VERSION "f32"

NS_ :

BS_:

BU_: C70 VC MCU BMS CHG DASH PBX

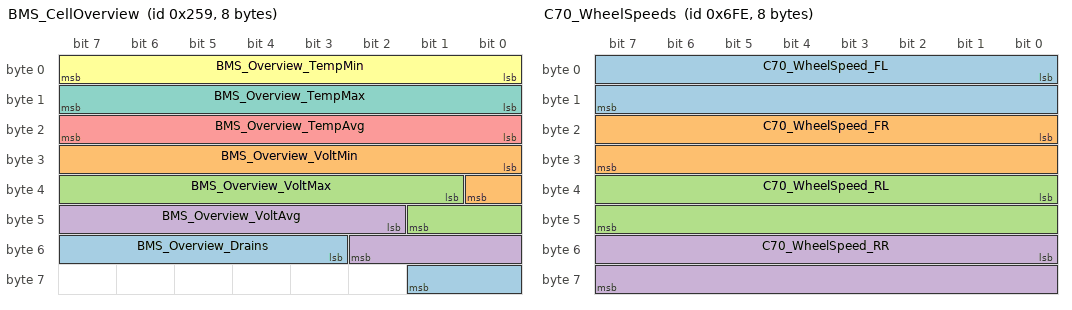
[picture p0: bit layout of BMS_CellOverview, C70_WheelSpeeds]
BO_ 601 BMS_CellOverview: 8 BMS
 SG_ BMS_Overview_Drains : 51|7@1+ (1,0) [0|76] "" Vector__XXX
 SG_ BMS_Overview_VoltMin : 24|9@1+ (0.01,0) [0|5.12] "V"  DASH
 SG_ BMS_Overview_VoltMax : 33|9@1+ (0.01,0) [0|5.12] "V"  DASH
 SG_ BMS_Overview_VoltAvg : 42|9@1+ (0.01,0) [0|5.12] "V" Vector__XXX
 SG_ BMS_Overview_TempAvg : 16|8@1- (1,0) [-128|127] "C" Vector__XXX
 SG_ BMS_Overview_TempMin : 0|8@1- (1,0) [-128|127] "C" Vector__XXX
 SG_ BMS_Overview_TempMax : 8|8@1- (1,0) [-128|127] "C" Vector__XXX

BO_ 1790 C70_WheelSpeeds: 8 C70
 SG_ C70_WheelSpeed_FL : 0|16@1- (1,0) [0|65536] ""  C70
 SG_ C70_WheelSpeed_FR : 16|16@1- (1,0) [0|65536] ""  C70
 SG_ C70_WheelSpeed_RL : 32|16@1- (1,0) [0|65536] ""  C70
 SG_ C70_WheelSpeed_RR : 48|16@1- (1,0) [0|65536] ""  C70

BO_ 1791 C70_BrakePressures: 8 C70
 SG_ C70_BrakePressureFront : 0|16@1+ (1,0) [0|5000] "psi" Vector__XXX
 SG_ C70_BrakePressureRear : 16|16@1- (0.2,1250) [0|2500] "psi" Vector__XXX

BO_ 301 VC_Status: 8 VC
 SG_ VC_Status_VehicleState : 0|4@1+ (1,0) [0|15] ""  DASH
 SG_ VC_Status_MC_State : 4|4@1+ (1,0) [0|15] ""  DASH

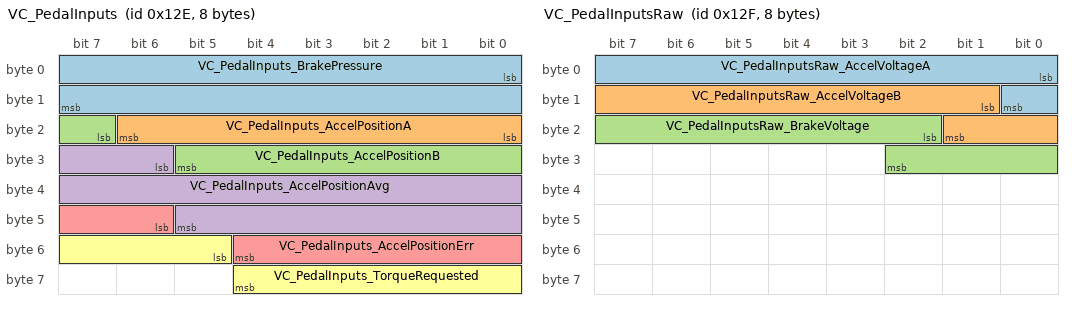
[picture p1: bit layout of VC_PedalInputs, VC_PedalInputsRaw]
BO_ 302 VC_PedalInputs: 8 VC
 SG_ VC_PedalInputs_BrakePressure : 0|16@1+ (0.1,0) [0|3000] "psi" Vector__XXX
 SG_ VC_PedalInputs_AccelPositionA : 16|7@1+ (1,0) [0|100] "%" Vector__XXX
 SG_ VC_PedalInputs_AccelPositionB : 23|7@1+ (1,0) [0|100] "%" Vector__XXX
 SG_ VC_PedalInputs_AccelPositionAvg : 30|16@1+ (0.1,0) [0|100] "%" Vector__XXX
 SG_ VC_PedalInputs_AccelPositionErr : 46|7@1+ (1,0) [0|100] "%" Vector__XXX
 SG_ VC_PedalInputs_TorqueRequested : 53|8@1+ (1,0) [0|254] "Nm" Vector__XXX

BO_ 303 VC_PedalInputsRaw: 8 VC
 SG_ VC_PedalInputsRaw_AccelVoltageA : 0|9@1+ (0.01,0) [0|5] "V" Vector__XXX
 SG_ VC_PedalInputsRaw_AccelVoltageB : 9|9@1+ (0.01,0) [0|5] "V" Vector__XXX
 SG_ VC_PedalInputsRaw_BrakeVoltage : 18|9@1+ (0.01,0) [0|5] "V" Vector__XXX

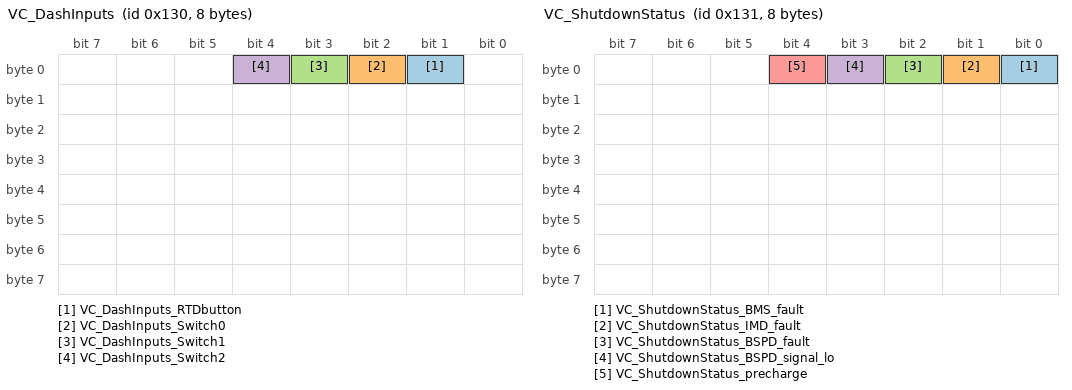
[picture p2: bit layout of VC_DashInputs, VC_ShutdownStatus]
BO_ 304 VC_DashInputs: 8 VC
 SG_ VC_DashInputs_RTDbutton : 1|1@1+ (1,0) [0|1] "" Vector__XXX
 SG_ VC_DashInputs_Switch0 : 2|1@1+ (1,0) [0|1] "" Vector__XXX
 SG_ VC_DashInputs_Switch1 : 3|1@1+ (1,0) [0|1] "" Vector__XXX
 SG_ VC_DashInputs_Switch2 : 4|1@1+ (1,0) [0|1] "" Vector__XXX

BO_ 305 VC_ShutdownStatus: 8 VC
 SG_ VC_ShutdownStatus_BMS_fault : 0|1@1+ (1,0) [0|1] "" Vector__XXX
 SG_ VC_ShutdownStatus_IMD_fault : 1|1@1+ (1,0) [0|1] "" Vector__XXX
 SG_ VC_ShutdownStatus_BSPD_fault : 2|1@1+ (1,0) [0|1] "" Vector__XXX
 SG_ VC_ShutdownStatus_BSPD_signal_lo : 3|1@1+ (1,0) [0|1] "" Vector__XXX
 SG_ VC_ShutdownStatus_precharge : 4|1@1+ (1,0) [0|1] "" Vector__XXX

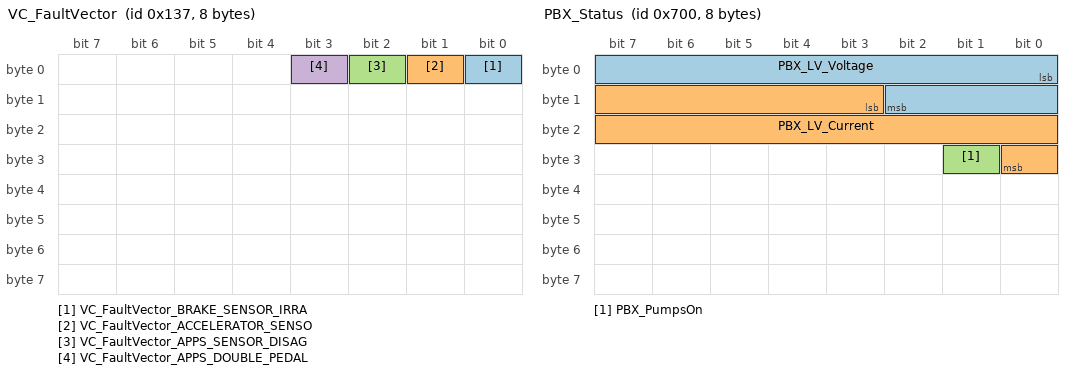
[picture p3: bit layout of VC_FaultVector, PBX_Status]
BO_ 311 VC_FaultVector: 8 VC
 SG_ VC_FaultVector_BRAKE_SENSOR_IRRA : 0|1@1+ (1,0) [0|1] ""  DASH
 SG_ VC_FaultVector_ACCELERATOR_SENSO : 1|1@1+ (1,0) [0|1] ""  DASH
 SG_ VC_FaultVector_APPS_SENSOR_DISAG : 2|1@1+ (1,0) [0|1] ""  DASH
 SG_ VC_FaultVector_APPS_DOUBLE_PEDAL : 3|1@1+ (1,0) [0|1] ""  DASH

BO_ 315 VC_HardFaultIndicator: 8 VC
 SG_ VC_HardFaultIndicator_task : 0|4@1+ (1,0) [0|15] ""  DASH

BO_ 316 VC_RTDSRequest: 8 VC
 SG_ VC_RequestRTDS : 0|1@1+ (1,0) [0|1] "" Vector__XXX

BO_ 1792 PBX_Status: 8 PBX
 SG_ PBX_LV_Voltage : 0|11@1+ (0.01,0) [0|20] "V" Vector__XXX
 SG_ PBX_LV_Current : 11|14@1+ (0.01,0) [0|100] "A" Vector__XXX
 SG_ PBX_PumpsOn : 25|1@1+ (1,0) [0|1] ""  VC

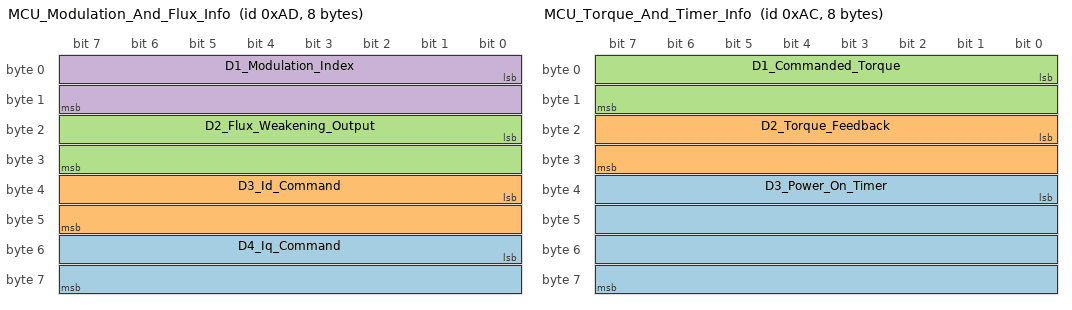
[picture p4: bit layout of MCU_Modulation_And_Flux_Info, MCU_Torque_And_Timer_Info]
BO_ 173 MCU_Modulation_And_Flux_Info: 8 MCU
 SG_ D4_Iq_Command : 48|16@1- (0.1,0) [-3276.8|3276.7] "A" Vector__XXX
 SG_ D3_Id_Command : 32|16@1- (0.1,0) [-3276.8|3276.7] "A" Vector__XXX
 SG_ D2_Flux_Weakening_Output : 16|16@1- (0.1,0) [-3276.8|3276.7] "A" Vector__XXX
 SG_ D1_Modulation_Index : 0|16@1- (0.0001,0) [-3.2768|3.2767] "" Vector__XXX

BO_ 172 MCU_Torque_And_Timer_Info: 8 MCU
 SG_ D3_Power_On_Timer : 32|32@1+ (0.003,0) [0|12884800] "Sec" Vector__XXX
 SG_ D2_Torque_Feedback : 16|16@1- (0.1,0) [-3276.8|3276.7] "Nm" Vector__XXX
 SG_ D1_Commanded_Torque : 0|16@1- (0.1,0) [-3276.8|3276.7] "Nm" Vector__XXX

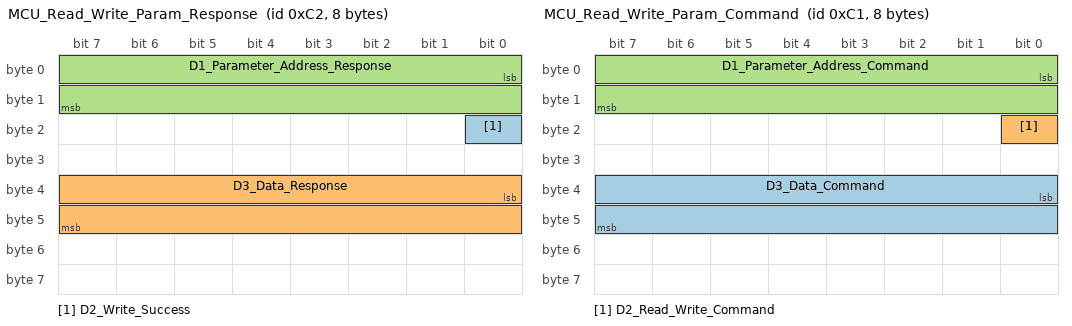
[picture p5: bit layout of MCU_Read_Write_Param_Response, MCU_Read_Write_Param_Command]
BO_ 194 MCU_Read_Write_Param_Response: 8 MCU
 SG_ D2_Write_Success : 16|1@1+ (1,0) [0|1] "" Vector__XXX
 SG_ D3_Data_Response : 32|16@1- (1,0) [-32768|32767] "" Vector__XXX
 SG_ D1_Parameter_Address_Response : 0|16@1+ (1,0) [0|65535] "" Vector__XXX

BO_ 193 MCU_Read_Write_Param_Command: 8 VC
 SG_ D3_Data_Command : 32|16@1- (1,0) [-32768|32767] ""  MCU
 SG_ D2_Read_Write_Command : 16|1@1+ (1,0) [0|1] ""  MCU
 SG_ D1_Parameter_Address_Command : 0|16@1+ (1,0) [0|65535] ""  MCU

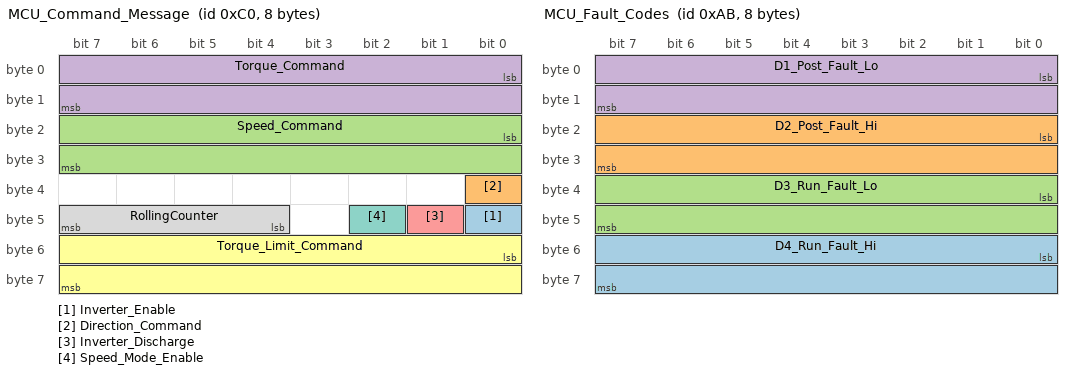
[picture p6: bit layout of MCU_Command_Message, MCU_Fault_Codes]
BO_ 192 MCU_Command_Message: 8 VC
 SG_ Inverter_Enable : 40|1@1+ (1,0) [0|1] "Bit"  MCU
 SG_ Direction_Command : 32|1@1+ (1,0) [0|1] "Bit"  MCU
 SG_ Speed_Command : 16|16@1- (1,0) [-32768|32767] "rpm"  MCU
 SG_ Torque_Command : 0|16@1- (0.1,0) [-3276.8|3276.7] "Nm"  MCU
 SG_ Inverter_Discharge : 41|1@1+ (1,0) [0|1] "Bit"  MCU
 SG_ Torque_Limit_Command : 48|16@1- (0.1,0) [-3276.8|3276.7] "Nm"  MCU
 SG_ Speed_Mode_Enable : 42|1@1+ (1,0) [0|1] "Bit"  MCU
 SG_ RollingCounter : 44|4@1+ (1,0) [0|15] "Bits"  MCU

BO_ 171 MCU_Fault_Codes: 8 MCU
 SG_ D4_Run_Fault_Hi : 48|16@1+ (1,0) [0|65535] "" Vector__XXX
 SG_ D2_Post_Fault_Hi : 16|16@1+ (1,0) [0|65535] "" Vector__XXX
 SG_ D3_Run_Fault_Lo : 32|16@1+ (1,0) [0|65535] "" Vector__XXX
 SG_ D1_Post_Fault_Lo : 0|16@1+ (1,0) [0|65535] "" Vector__XXX

BO_ 170 MCU_Internal_States: 8 MCU
 SG_ D7_Direction_Command : 56|1@1+ (1,0) [0|1] "" Vector__XXX
 SG_ D6_Inverter_Enable_State : 48|1@1+ (1,0) [0|1] "" Vector__XXX
 SG_ D3_Relay_3_Status : 26|1@1+ (1,0) [0|1] "" Vector__XXX
 SG_ D3_Relay_4_Status : 27|1@1+ (1,0) [0|1] "" Vector__XXX
 SG_ D3_Relay_2_Status : 25|1@1+ (1,0) [0|1] "" Vector__XXX
 SG_ D4_Inverter_Run_Mode : 32|1@1+ (1,0) [0|1] "" Vector__XXX
 SG_ D5_Inverter_Command_Mode : 40|1@1+ (1,0) [0|1] "" Vector__XXX
 SG_ D3_Relay_1_Status : 24|1@1+ (1,0) [0|1] "" Vector__XXX
 SG_ D2_Inverter_State : 16|8@1+ (1,0) [0|255] "" Vector__XXX
 SG_ D1_VSM_State : 0|8@1+ (1,0) [0|15] "" Vector__XXX
 SG_ D6_Inverter_Enable_Lockout : 55|1@1+ (1,0) [0|1] "" Vector__XXX
 SG_ D4_Inverter_Discharge_State : 37|3@1+ (1,0) [0|7] "" Vector__XXX
 SG_ D3_Relay_5_Status : 28|1@1+ (1,0) [0|1] "" Vector__XXX
 SG_ D3_Relay_6_Status : 29|1@1+ (1,0) [0|1] "" Vector__XXX
 SG_ D7_BMS_Active : 57|1@1+ (1,0) [0|1] "" Vector__XXX
 SG_ D7_BMS_Torque_Limiting : 58|1@1+ (1,0) [0|1] "" Vector__XXX
 SG_ D7_Max_Speed_Limiting : 59|1@1+ (1,0) [0|1] "" Vector__XXX
 SG_ D7_Low_Speed_Limiting : 61|1@1+ (1,0) [0|1] "" Vector__XXX
 SG_ D5_Rolling_Counter : 44|4@1+ (1,0) [0|15] "" Vector__XXX
 SG_ D1_PWM_Frequency : 8|8@1+ (1,0) [0|255] "kHz" Vector__XXX
 SG_ D6_Start_Mode_Active : 54|1@1+ (1,0) [0|1] "" Vector__XXX

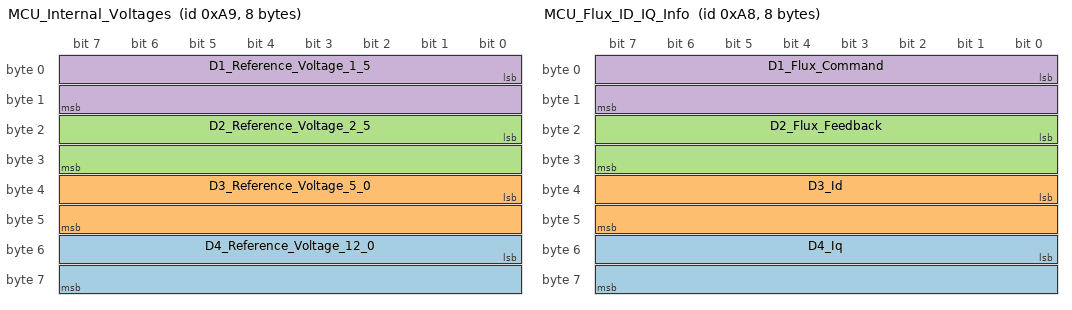
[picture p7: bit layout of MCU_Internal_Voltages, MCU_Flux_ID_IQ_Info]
BO_ 169 MCU_Internal_Voltages: 8 MCU
 SG_ D4_Reference_Voltage_12_0 : 48|16@1- (0.01,0) [-327.68|327.67] "V" Vector__XXX
 SG_ D3_Reference_Voltage_5_0 : 32|16@1- (0.01,0) [-327.68|327.67] "V" Vector__XXX
 SG_ D2_Reference_Voltage_2_5 : 16|16@1- (0.01,0) [-327.68|327.67] "V" Vector__XXX
 SG_ D1_Reference_Voltage_1_5 : 0|16@1- (0.01,0) [-327.68|327.67] "V" Vector__XXX

BO_ 168 MCU_Flux_ID_IQ_Info: 8 MCU
 SG_ D4_Iq : 48|16@1- (0.1,0) [-3276.8|3276.7] "A" Vector__XXX
 SG_ D3_Id : 32|16@1- (0.1,0) [-3276.8|3276.7] "A" Vector__XXX
 SG_ D2_Flux_Feedback : 16|16@1- (0.001,0) [-32.768|32.767] "Wb" Vector__XXX
 SG_ D1_Flux_Command : 0|16@1- (0.001,0) [-32.768|32.767] "Wb" Vector__XXX

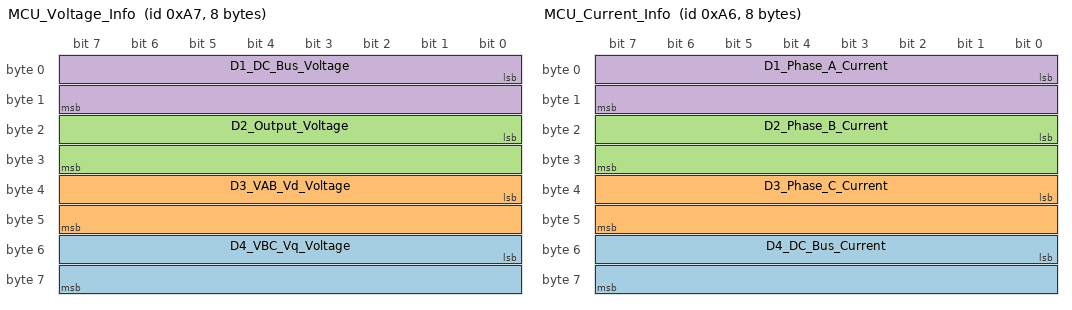
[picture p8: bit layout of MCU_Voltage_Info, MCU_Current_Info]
BO_ 167 MCU_Voltage_Info: 8 MCU
 SG_ D4_VBC_Vq_Voltage : 48|16@1- (0.1,0) [-3276.8|3276.7] "V" Vector__XXX
 SG_ D3_VAB_Vd_Voltage : 32|16@1- (0.1,0) [-3276.8|3276.7] "V" Vector__XXX
 SG_ D2_Output_Voltage : 16|16@1- (0.1,0) [-3276.8|3276.7] "V" Vector__XXX
 SG_ D1_DC_Bus_Voltage : 0|16@1- (0.1,0) [-3276.8|3276.7] "V" Vector__XXX

BO_ 166 MCU_Current_Info: 8 MCU
 SG_ D4_DC_Bus_Current : 48|16@1- (0.1,0) [-3276.8|3276.7] "A" Vector__XXX
 SG_ D3_Phase_C_Current : 32|16@1- (0.1,0) [-3276.8|3276.7] "A" Vector__XXX
 SG_ D2_Phase_B_Current : 16|16@1- (0.1,0) [-3276.8|3276.7] "A" Vector__XXX
 SG_ D1_Phase_A_Current : 0|16@1- (0.1,0) [-3276.8|3276.7] "A" Vector__XXX

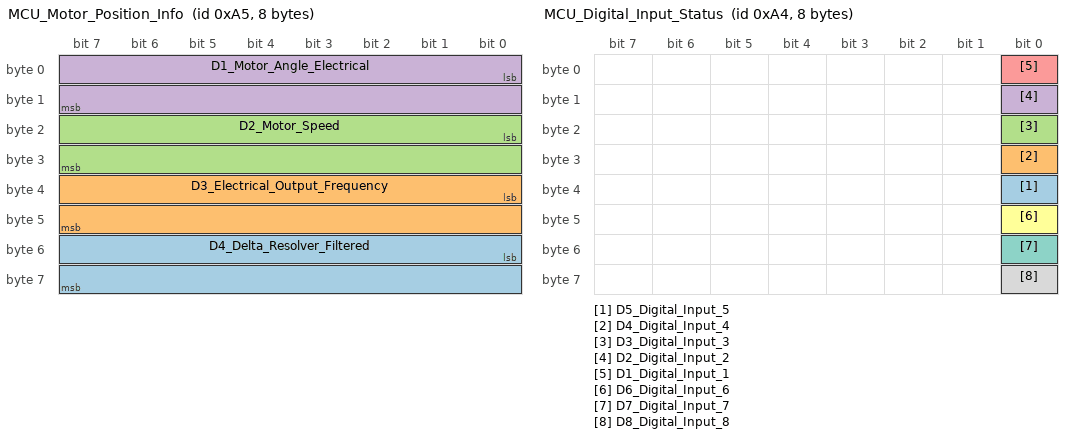
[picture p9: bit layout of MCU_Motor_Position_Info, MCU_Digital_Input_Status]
BO_ 165 MCU_Motor_Position_Info: 8 MCU
 SG_ D4_Delta_Resolver_Filtered : 48|16@1- (0.1,0) [-3276.8|3276.7] "deg" Vector__XXX
 SG_ D3_Electrical_Output_Frequency : 32|16@1- (0.1,0) [-3276.8|3276.7] "hz" Vector__XXX
 SG_ D2_Motor_Speed : 16|16@1- (1,0) [-32768|32767] "rpm"  DASH
 SG_ D1_Motor_Angle_Electrical : 0|16@1+ (0.1,0) [0|6553.5] "deg" Vector__XXX

BO_ 164 MCU_Digital_Input_Status: 8 MCU
 SG_ D5_Digital_Input_5 : 32|1@1+ (1,0) [0|1] "boolean" Vector__XXX
 SG_ D4_Digital_Input_4 : 24|1@1+ (1,0) [0|1] "boolean" Vector__XXX
 SG_ D3_Digital_Input_3 : 16|1@1+ (1,0) [0|1] "boolean" Vector__XXX
 SG_ D2_Digital_Input_2 : 8|1@1+ (1,0) [0|1] "boolean" Vector__XXX
 SG_ D1_Digital_Input_1 : 0|1@1+ (1,0) [0|1] "boolean" Vector__XXX
 SG_ D6_Digital_Input_6 : 40|1@1+ (1,0) [0|1] "boolean" Vector__XXX
 SG_ D7_Digital_Input_7 : 48|1@1+ (1,0) [0|1] "boolean" Vector__XXX
 SG_ D8_Digital_Input_8 : 56|1@1+ (1,0) [0|1] "boolean" Vector__XXX

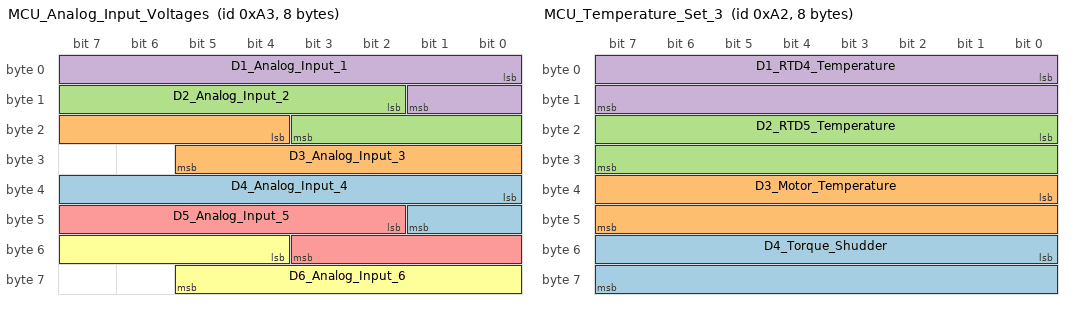
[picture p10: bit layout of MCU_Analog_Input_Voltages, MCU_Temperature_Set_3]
BO_ 163 MCU_Analog_Input_Voltages: 8 MCU
 SG_ D4_Analog_Input_4 : 32|10@1+ (0.01,0) [0|10.23] "V" Vector__XXX
 SG_ D3_Analog_Input_3 : 20|10@1+ (0.01,0) [0|10.23] "V" Vector__XXX
 SG_ D2_Analog_Input_2 : 10|10@1+ (0.01,0) [0|10.23] "V" Vector__XXX
 SG_ D1_Analog_Input_1 : 0|10@1+ (0.01,0) [0|10.23] "V" Vector__XXX
 SG_ D5_Analog_Input_5 : 42|10@1+ (0.01,0) [0|10.23] "V" Vector__XXX
 SG_ D6_Analog_Input_6 : 52|10@1+ (0.01,0) [0|10.23] "V" Vector__XXX

BO_ 162 MCU_Temperature_Set_3: 8 MCU
 SG_ D4_Torque_Shudder : 48|16@1- (0.1,0) [-3276.8|3276.7] "Nm" Vector__XXX
 SG_ D3_Motor_Temperature : 32|16@1- (0.1,0) [-3276.8|3276.7] "degC" Vector__XXX
 SG_ D2_RTD5_Temperature : 16|16@1- (0.1,0) [-3276.8|3276.7] "degC" Vector__XXX
 SG_ D1_RTD4_Temperature : 0|16@1- (0.1,0) [-3276.8|3276.7] "degC" Vector__XXX

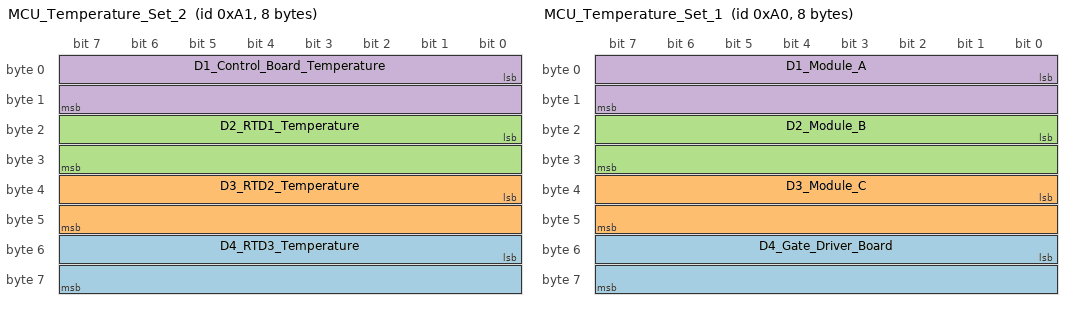
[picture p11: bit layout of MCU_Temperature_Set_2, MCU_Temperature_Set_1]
BO_ 161 MCU_Temperature_Set_2: 8 MCU
 SG_ D4_RTD3_Temperature : 48|16@1- (0.1,0) [-3276.8|3276.7] "degC" Vector__XXX
 SG_ D3_RTD2_Temperature : 32|16@1- (0.1,0) [-3276.8|3276.7] "degC" Vector__XXX
 SG_ D2_RTD1_Temperature : 16|16@1- (0.1,0) [-3276.8|3276.7] "degC" Vector__XXX
 SG_ D1_Control_Board_Temperature : 0|16@1- (0.1,0) [-3276.8|3276.7] "degC" Vector__XXX

BO_ 160 MCU_Temperature_Set_1: 8 MCU
 SG_ D4_Gate_Driver_Board : 48|16@1- (0.1,0) [-3276.8|3276.7] "degC" Vector__XXX
 SG_ D3_Module_C : 32|16@1- (0.1,0) [-3276.8|3276.7] "degC" Vector__XXX
 SG_ D2_Module_B : 16|16@1- (0.1,0) [-3276.8|3276.7] "degC" Vector__XXX
 SG_ D1_Module_A : 0|16@1- (0.1,0) [-3276.8|3276.7] "degC" Vector__XXX

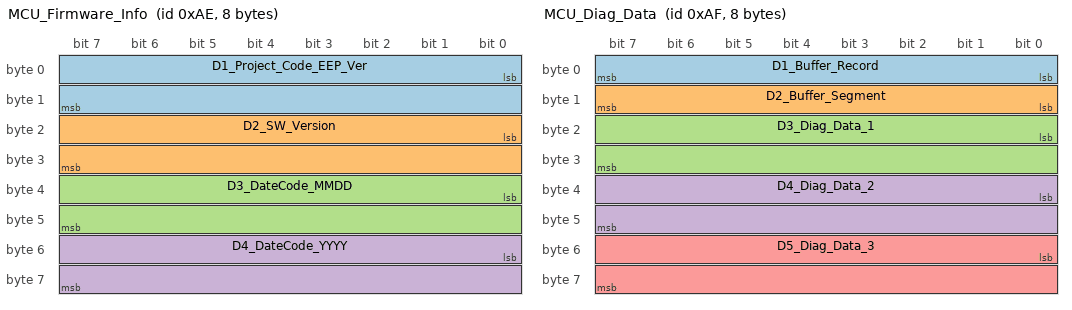
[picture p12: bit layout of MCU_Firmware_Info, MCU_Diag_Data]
BO_ 174 MCU_Firmware_Info: 8 MCU
 SG_ D1_Project_Code_EEP_Ver : 0|16@1+ (1,0) [0|65535] "" Vector__XXX
 SG_ D2_SW_Version : 16|16@1+ (1,0) [0|65535] "" Vector__XXX
 SG_ D3_DateCode_MMDD : 32|16@1+ (1,0) [0|65535] "" Vector__XXX
 SG_ D4_DateCode_YYYY : 48|16@1+ (1,0) [0|65535] "" Vector__XXX

BO_ 175 MCU_Diag_Data: 8 MCU
 SG_ D1_Buffer_Record : 0|8@1+ (1,0) [0|255] "" Vector__XXX
 SG_ D2_Buffer_Segment : 8|8@1+ (1,0) [0|5] "" Vector__XXX
 SG_ D3_Diag_Data_1 : 16|16@1- (1,0) [-32768|32767] "" Vector__XXX
 SG_ D4_Diag_Data_2 : 32|16@1- (1,0) [-32768|32767] "" Vector__XXX
 SG_ D5_Diag_Data_3 : 48|16@1- (1,0) [-32768|32767] "" Vector__XXX

BO_ 471 MCU_U2C_Command_Txd: 8 MCU
 SG_ D1_ID_Byte : 0|8@1+ (1,0) [0|255] "" Vector__XXX
 SG_ D2_Setpoint_Calc : 8|8@1+ (1,0) [0|255] "" Vector__XXX

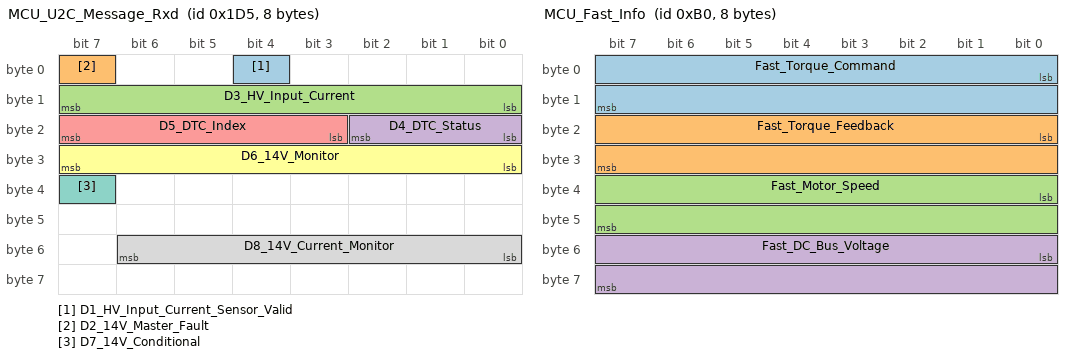
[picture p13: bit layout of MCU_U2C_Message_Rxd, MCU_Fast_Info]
BO_ 469 MCU_U2C_Message_Rxd: 8 MCU
 SG_ D1_HV_Input_Current_Sensor_Valid : 4|1@1+ (1,0) [0|1] "" Vector__XXX
 SG_ D2_14V_Master_Fault : 7|1@1+ (1,0) [0|1] "" Vector__XXX
 SG_ D3_HV_Input_Current : 8|8@1+ (1,0) [0|255] "" Vector__XXX
 SG_ D4_DTC_Status : 16|3@1+ (1,0) [0|7] "" Vector__XXX
 SG_ D5_DTC_Index : 19|5@1+ (1,0) [0|31] "" Vector__XXX
 SG_ D6_14V_Monitor : 24|8@1+ (1,0) [0|255] "" Vector__XXX
 SG_ D7_14V_Conditional : 39|1@1+ (1,0) [0|1] "" Vector__XXX
 SG_ D8_14V_Current_Monitor : 48|7@1+ (1,0) [0|127] "" Vector__XXX

BO_ 514 BMS_Current_Limit: 8 BMS
 SG_ D1_Max_Discharge_Current : 0|16@1+ (1,0) [0|1000] "A" Vector__XXX
 SG_ D2_Max_Charge_Current : 16|16@1+ (1,0) [0|1000] "A" Vector__XXX

BO_ 176 MCU_Fast_Info: 8 MCU
 SG_ Fast_Torque_Command : 0|16@1- (0.1,0) [-3276.8|3276.7] "Nm" Vector__XXX
 SG_ Fast_Torque_Feedback : 16|16@1- (0.1,0) [-3276.8|3276.7] "Nm" Vector__XXX
 SG_ Fast_Motor_Speed : 32|16@1- (1,0) [-32768|32767] "rpm" Vector__XXX
 SG_ Fast_DC_Bus_Voltage : 48|16@1- (0.1,0) [-3276.8|3276.7] "V" Vector__XXX

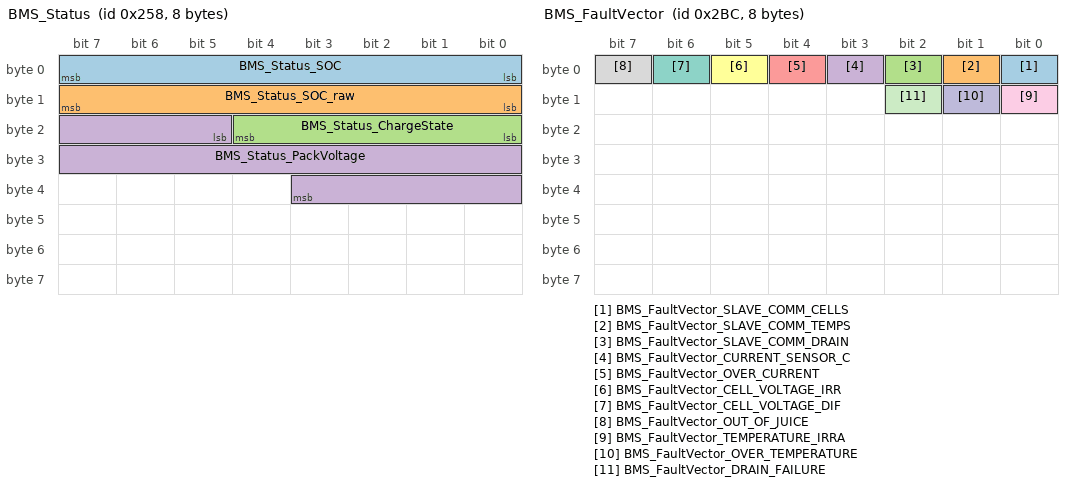
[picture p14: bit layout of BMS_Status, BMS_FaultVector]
BO_ 600 BMS_Status: 8 BMS
 SG_ BMS_Status_SOC : 0|8@1+ (1,0) [0|100] "%"  DASH
 SG_ BMS_Status_SOC_raw : 8|8@1+ (1,0) [0|100] "%" Vector__XXX
 SG_ BMS_Status_ChargeState : 16|5@1+ (1,0) [0|4] "" Vector__XXX
 SG_ BMS_Status_PackVoltage : 21|15@1+ (0.1,0) [0|400] "V"  DASH

BO_ 700 BMS_FaultVector: 8 BMS
 SG_ BMS_FaultVector_SLAVE_COMM_CELLS : 0|1@1+ (1,0) [0|1] ""  DASH
 SG_ BMS_FaultVector_SLAVE_COMM_TEMPS : 1|1@1+ (1,0) [0|1] ""  DASH
 SG_ BMS_FaultVector_SLAVE_COMM_DRAIN : 2|1@1+ (1,0) [0|1] ""  DASH
 SG_ BMS_FaultVector_CURRENT_SENSOR_C : 3|1@1+ (1,0) [0|1] ""  DASH
 SG_ BMS_FaultVector_OVER_CURRENT : 4|1@1+ (1,0) [0|1] ""  DASH
 SG_ BMS_FaultVector_CELL_VOLTAGE_IRR : 5|1@1+ (1,0) [0|1] ""  DASH
 SG_ BMS_FaultVector_CELL_VOLTAGE_DIF : 6|1@1+ (1,0) [0|1] ""  DASH
 SG_ BMS_FaultVector_OUT_OF_JUICE : 7|1@1+ (1,0) [0|1] ""  DASH
 SG_ BMS_FaultVector_TEMPERATURE_IRRA : 8|1@1+ (1,0) [0|1] ""  DASH
 SG_ BMS_FaultVector_OVER_TEMPERATURE : 9|1@1+ (1,0) [0|1] ""  DASH
 SG_ BMS_FaultVector_DRAIN_FAILURE : 10|1@1+ (1,0) [0|1] ""  DASH

BO_ 701 BMS_FaultAlert: 8 BMS
 SG_ BMS_FaultAlert_code M : 0|6@1+ (1,0) [0|63] "" Vector__XXX
 SG_ BMS_FaultAlert_cell_comm_slave_b m0 : 6|8@1+ (1,0) [0|255] "" Vector__XXX
 SG_ BMS_FaultAlert_temp_comm_slave_b m1 : 6|8@1+ (1,0) [0|255] "" Vector__XXX
 SG_ BMS_FaultAlert_drain_comm_slave_ m2 : 6|8@1+ (1,0) [0|255] "" Vector__XXX
 SG_ BMS_FaultAlert_adc_error_code m3 : 6|8@1+ (1,0) [0|255] "" Vector__XXX
 SG_ BMS_FaultAlert_current m4 : 6|32@1+ (0.001,0) [0|2000] "A" Vector__XXX
 SG_ BMS_FaultAlert_irrational_voltag m5 : 6|9@1+ (0.01,0) [0|5.12] "V" Vector__XXX
 SG_ BMS_FaultAlert_voltage_diff m6 : 6|9@1+ (0.01,0) [0|5.12] "V" Vector__XXX
 SG_ BMS_FaultAlert_lowest_cell_volta m7 : 6|9@1+ (0.01,0) [0|5.12] "V" Vector__XXX
 SG_ BMS_FaultAlert_irrational_temper m8 : 6|16@1+ (0.01,0) [-327.68|327.67] "V" Vector__XXX
 SG_ BMS_FaultAlert_over_temperature m9 : 6|16@1+ (0.01,0) [-327.68|327.67] "V" Vector__XXX
 SG_ BMS_FaultAlert_failed_drain_cell m10 : 6|8@1+ (1,0) [0|255] "" Vector__XXX

BO_ 702 BMS_Voltages: 8 BMS
 SG_ BMS_Voltages_mux M : 0|8@1+ (1,0) [0|12] "" Vector__XXX
 SG_ BMS_Voltages_Seg1_Cell1 m0 : 8|9@1+ (0.01,0) [0|5.12] "V" Vector__XXX
 SG_ BMS_Voltages_Seg1_Cell2 m0 : 17|9@1+ (0.01,0) [0|5.12] "V" Vector__XXX
 SG_ BMS_Voltages_Seg1_Cell3 m0 : 26|9@1+ (0.01,0) [0|5.12] "V" Vector__XXX
 SG_ BMS_Voltages_Seg1_Cell4 m0 : 35|9@1+ (0.01,0) [0|5.12] "V" Vector__XXX
 SG_ BMS_Voltages_Seg1_Cell5 m0 : 44|9@1+ (0.01,0) [0|5.12] "V" Vector__XXX
 SG_ BMS_Voltages_Seg1_Cell6 m0 : 53|9@1+ (0.01,0) [0|5.12] "V" Vector__XXX
 SG_ BMS_Voltages_Seg1_Cell7 m1 : 8|9@1+ (0.01,0) [0|5.12] "V" Vector__XXX
 SG_ BMS_Voltages_Seg1_Cell8 m1 : 17|9@1+ (0.01,0) [0|5.12] "V" Vector__XXX
 SG_ BMS_Voltages_Seg1_Cell9 m1 : 26|9@1+ (0.01,0) [0|5.12] "V" Vector__XXX
 SG_ BMS_Voltages_Seg1_Cell10 m1 : 35|9@1+ (0.01,0) [0|5.12] "V" Vector__XXX
 SG_ BMS_Voltages_Seg1_Cell11 m1 : 44|9@1+ (0.01,0) [0|5.12] "V" Vector__XXX
 SG_ BMS_Voltages_Seg1_Cell12 m1 : 53|9@1+ (0.01,0) [0|5.12] "V" Vector__XXX
 SG_ BMS_Voltages_Seg1_Cell13 m2 : 8|9@1+ (0.01,0) [0|5.12] "V" Vector__XXX
 SG_ BMS_Voltages_Seg1_Cell14 m2 : 17|9@1+ (0.01,0) [0|5.12] "V" Vector__XXX
 SG_ BMS_Voltages_Seg1_Cell15 m2 : 26|9@1+ (0.01,0) [0|5.12] "V" Vector__XXX
 SG_ BMS_Voltages_Seg1_Cell16 m2 : 35|9@1+ (0.01,0) [0|5.12] "V" Vector__XXX
 SG_ BMS_Voltages_Seg1_Cell17 m2 : 44|9@1+ (0.01,0) [0|5.12] "V" Vector__XXX
 SG_ BMS_Voltages_Seg1_Cell18 m2 : 53|9@1+ (0.01,0) [0|5.12] "V" Vector__XXX
 SG_ BMS_Voltages_Seg1_Cell19 m3 : 8|9@1+ (0.01,0) [0|5.12] "V" Vector__XXX
 SG_ BMS_Voltages_Seg2_Cell1 m3 : 17|9@1+ (0.01,0) [0|5.12] "V" Vector__XXX
 SG_ BMS_Voltages_Seg2_Cell2 m3 : 26|9@1+ (0.01,0) [0|5.12] "V" Vector__XXX
 SG_ BMS_Voltages_Seg2_Cell3 m3 : 35|9@1+ (0.01,0) [0|5.12] "V" Vector__XXX
 SG_ BMS_Voltages_Seg2_Cell4 m3 : 44|9@1+ (0.01,0) [0|5.12] "V" Vector__XXX
 SG_ BMS_Voltages_Seg2_Cell5 m3 : 53|9@1+ (0.01,0) [0|5.12] "V" Vector__XXX
 SG_ BMS_Voltages_Seg2_Cell6 m4 : 8|9@1+ (0.01,0) [0|5.12] "V" Vector__XXX
 SG_ BMS_Voltages_Seg2_Cell7 m4 : 17|9@1+ (0.01,0) [0|5.12] "V" Vector__XXX
 SG_ BMS_Voltages_Seg2_Cell8 m4 : 26|9@1+ (0.01,0) [0|5.12] "V" Vector__XXX
 SG_ BMS_Voltages_Seg2_Cell9 m4 : 35|9@1+ (0.01,0) [0|5.12] "V" Vector__XXX
 SG_ BMS_Voltages_Seg2_Cell10 m4 : 44|9@1+ (0.01,0) [0|5.12] "V" Vector__XXX
 SG_ BMS_Voltages_Seg2_Cell11 m4 : 53|9@1+ (0.01,0) [0|5.12] "V" Vector__XXX
 SG_ BMS_Voltages_Seg2_Cell12 m5 : 8|9@1+ (0.01,0) [0|5.12] "V" Vector__XXX
 SG_ BMS_Voltages_Seg2_Cell13 m5 : 17|9@1+ (0.01,0) [0|5.12] "V" Vector__XXX
 SG_ BMS_Voltages_Seg2_Cell14 m5 : 26|9@1+ (0.01,0) [0|5.12] "V" Vector__XXX
 SG_ BMS_Voltages_Seg2_Cell15 m5 : 35|9@1+ (0.01,0) [0|5.12] "V" Vector__XXX
 SG_ BMS_Voltages_Seg2_Cell16 m5 : 44|9@1+ (0.01,0) [0|5.12] "V" Vector__XXX
 SG_ BMS_Voltages_Seg2_Cell17 m5 : 53|9@1+ (0.01,0) [0|5.12] "V" Vector__XXX
 SG_ BMS_Voltages_Seg2_Cell18 m6 : 8|9@1+ (0.01,0) [0|5.12] "V" Vector__XXX
 SG_ BMS_Voltages_Seg2_Cell19 m6 : 17|9@1+ (0.01,0) [0|5.12] "V" Vector__XXX
 SG_ BMS_Voltages_Seg3_Cell1 m6 : 26|9@1+ (0.01,0) [0|5.12] "V" Vector__XXX
 SG_ BMS_Voltages_Seg3_Cell2 m6 : 35|9@1+ (0.01,0) [0|5.12] "V" Vector__XXX
 SG_ BMS_Voltages_Seg3_Cell3 m6 : 44|9@1+ (0.01,0) [0|5.12] "V" Vector__XXX
 SG_ BMS_Voltages_Seg3_Cell4 m6 : 53|9@1+ (0.01,0) [0|5.12] "V" Vector__XXX
 SG_ BMS_Voltages_Seg3_Cell5 m7 : 8|9@1+ (0.01,0) [0|5.12] "V" Vector__XXX
 SG_ BMS_Voltages_Seg3_Cell6 m7 : 17|9@1+ (0.01,0) [0|5.12] "V" Vector__XXX
 SG_ BMS_Voltages_Seg3_Cell7 m7 : 26|9@1+ (0.01,0) [0|5.12] "V" Vector__XXX
 SG_ BMS_Voltages_Seg3_Cell8 m7 : 35|9@1+ (0.01,0) [0|5.12] "V" Vector__XXX
 SG_ BMS_Voltages_Seg3_Cell9 m7 : 44|9@1+ (0.01,0) [0|5.12] "V" Vector__XXX
 SG_ BMS_Voltages_Seg3_Cell10 m7 : 53|9@1+ (0.01,0) [0|5.12] "V" Vector__XXX
 SG_ BMS_Voltages_Seg3_Cell11 m8 : 8|9@1+ (0.01,0) [0|5.12] "V" Vector__XXX
 SG_ BMS_Voltages_Seg3_Cell12 m8 : 17|9@1+ (0.01,0) [0|5.12] "V" Vector__XXX
 SG_ BMS_Voltages_Seg3_Cell13 m8 : 26|9@1+ (0.01,0) [0|5.12] "V" Vector__XXX
 SG_ BMS_Voltages_Seg3_Cell14 m8 : 35|9@1+ (0.01,0) [0|5.12] "V" Vector__XXX
 SG_ BMS_Voltages_Seg3_Cell15 m8 : 44|9@1+ (0.01,0) [0|5.12] "V" Vector__XXX
 SG_ BMS_Voltages_Seg3_Cell16 m8 : 53|9@1+ (0.01,0) [0|5.12] "V" Vector__XXX
 SG_ BMS_Voltages_Seg3_Cell17 m9 : 8|9@1+ (0.01,0) [0|5.12] "V" Vector__XXX
 SG_ BMS_Voltages_Seg3_Cell18 m9 : 17|9@1+ (0.01,0) [0|5.12] "V" Vector__XXX
 SG_ BMS_Voltages_Seg3_Cell19 m9 : 26|9@1+ (0.01,0) [0|5.12] "V" Vector__XXX
 SG_ BMS_Voltages_Seg4_Cell1 m9 : 35|9@1+ (0.01,0) [0|5.12] "V" Vector__XXX
 SG_ BMS_Voltages_Seg4_Cell2 m9 : 44|9@1+ (0.01,0) [0|5.12] "V" Vector__XXX
 SG_ BMS_Voltages_Seg4_Cell3 m9 : 53|9@1+ (0.01,0) [0|5.12] "V" Vector__XXX
 SG_ BMS_Voltages_Seg4_Cell4 m10 : 8|9@1+ (0.01,0) [0|5.12] "V" Vector__XXX
 SG_ BMS_Voltages_Seg4_Cell5 m10 : 17|9@1+ (0.01,0) [0|5.12] "V" Vector__XXX
 SG_ BMS_Voltages_Seg4_Cell6 m10 : 26|9@1+ (0.01,0) [0|5.12] "V" Vector__XXX
 SG_ BMS_Voltages_Seg4_Cell7 m10 : 35|9@1+ (0.01,0) [0|5.12] "V" Vector__XXX
 SG_ BMS_Voltages_Seg4_Cell8 m10 : 44|9@1+ (0.01,0) [0|5.12] "V" Vector__XXX
 SG_ BMS_Voltages_Seg4_Cell9 m10 : 53|9@1+ (0.01,0) [0|5.12] "V" Vector__XXX
 SG_ BMS_Voltages_Seg4_Cell10 m11 : 8|9@1+ (0.01,0) [0|5.12] "V" Vector__XXX
 SG_ BMS_Voltages_Seg4_Cell11 m11 : 17|9@1+ (0.01,0) [0|5.12] "V" Vector__XXX
 SG_ BMS_Voltages_Seg4_Cell12 m11 : 26|9@1+ (0.01,0) [0|5.12] "V" Vector__XXX
 SG_ BMS_Voltages_Seg4_Cell13 m11 : 35|9@1+ (0.01,0) [0|5.12] "V" Vector__XXX
 SG_ BMS_Voltages_Seg4_Cell14 m11 : 44|9@1+ (0.01,0) [0|5.12] "V" Vector__XXX
 SG_ BMS_Voltages_Seg4_Cell15 m11 : 53|9@1+ (0.01,0) [0|5.12] "V" Vector__XXX
 SG_ BMS_Voltages_Seg4_Cell16 m12 : 8|9@1+ (0.01,0) [0|5.12] "V" Vector__XXX
 SG_ BMS_Voltages_Seg4_Cell17 m12 : 17|9@1+ (0.01,0) [0|5.12] "V" Vector__XXX
 SG_ BMS_Voltages_Seg4_Cell18 m12 : 26|9@1+ (0.01,0) [0|5.12] "V" Vector__XXX
 SG_ BMS_Voltages_Seg4_Cell19 m12 : 35|9@1+ (0.01,0) [0|5.12] "V" Vector__XXX

BO_ 703 BMS_ThermistorVoltages: 8 BMS
 SG_ BMS_ThermistorVoltages_mux M : 0|3@1+ (1,0) [0|5] "" Vector__XXX
 SG_ BMS_ThermistorVoltages_Seg1_tm1 m0 : 3|9@1+ (0.01,0) [0|5.12] "V" Vector__XXX
 SG_ BMS_ThermistorVoltages_Seg1_tm2 m0 : 12|9@1+ (0.01,0) [0|5.12] "V" Vector__XXX
 SG_ BMS_ThermistorVoltages_Seg1_tm3 m0 : 21|9@1+ (0.01,0) [0|5.12] "V" Vector__XXX
 SG_ BMS_ThermistorVoltages_Seg1_tm4 m0 : 30|9@1+ (0.01,0) [0|5.12] "V" Vector__XXX
 SG_ BMS_ThermistorVoltages_Seg1_tm5 m0 : 39|9@1+ (0.01,0) [0|5.12] "V" Vector__XXX
 SG_ BMS_ThermistorVoltages_Seg1_tm6 m0 : 48|9@1+ (0.01,0) [0|5.12] "V" Vector__XXX
 SG_ BMS_ThermistorVoltages_Seg1_tm7 m1 : 3|9@1+ (0.01,0) [0|5.12] "V" Vector__XXX
 SG_ BMS_ThermistorVoltages_Seg1_tm8 m1 : 12|9@1+ (0.01,0) [0|5.12] "V" Vector__XXX
 SG_ BMS_ThermistorVoltages_Seg2_tm1 m1 : 21|9@1+ (0.01,0) [0|5.12] "V" Vector__XXX
 SG_ BMS_ThermistorVoltages_Seg2_tm2 m1 : 30|9@1+ (0.01,0) [0|5.12] "V" Vector__XXX
 SG_ BMS_ThermistorVoltages_Seg2_tm3 m1 : 39|9@1+ (0.01,0) [0|5.12] "V" Vector__XXX
 SG_ BMS_ThermistorVoltages_Seg2_tm4 m1 : 48|9@1+ (0.01,0) [0|5.12] "V" Vector__XXX
 SG_ BMS_ThermistorVoltages_Seg2_tm5 m2 : 3|9@1+ (0.01,0) [0|5.12] "V" Vector__XXX
 SG_ BMS_ThermistorVoltages_Seg2_tm6 m2 : 12|9@1+ (0.01,0) [0|5.12] "V" Vector__XXX
 SG_ BMS_ThermistorVoltages_Seg2_tm7 m2 : 21|9@1+ (0.01,0) [0|5.12] "V" Vector__XXX
 SG_ BMS_ThermistorVoltages_Seg2_tm8 m2 : 30|9@1+ (0.01,0) [0|5.12] "V" Vector__XXX
 SG_ BMS_ThermistorVoltages_Seg3_tm1 m2 : 39|9@1+ (0.01,0) [0|5.12] "V" Vector__XXX
 SG_ BMS_ThermistorVoltages_Seg3_tm2 m2 : 48|9@1+ (0.01,0) [0|5.12] "V" Vector__XXX
 SG_ BMS_ThermistorVoltages_Seg3_tm3 m3 : 3|9@1+ (0.01,0) [0|5.12] "V" Vector__XXX
 SG_ BMS_ThermistorVoltages_Seg3_tm4 m3 : 12|9@1+ (0.01,0) [0|5.12] "V" Vector__XXX
 SG_ BMS_ThermistorVoltages_Seg3_tm5 m3 : 21|9@1+ (0.01,0) [0|5.12] "V" Vector__XXX
 SG_ BMS_ThermistorVoltages_Seg3_tm6 m3 : 30|9@1+ (0.01,0) [0|5.12] "V" Vector__XXX
 SG_ BMS_ThermistorVoltages_Seg3_tm7 m3 : 39|9@1+ (0.01,0) [0|5.12] "V" Vector__XXX
 SG_ BMS_ThermistorVoltages_Seg3_tm8 m3 : 48|9@1+ (0.01,0) [0|5.12] "V" Vector__XXX
 SG_ BMS_ThermistorVoltages_Seg4_tm1 m4 : 3|9@1+ (0.01,0) [0|5.12] "V" Vector__XXX
 SG_ BMS_ThermistorVoltages_Seg4_tm2 m4 : 12|9@1+ (0.01,0) [0|5.12] "V" Vector__XXX
 SG_ BMS_ThermistorVoltages_Seg4_tm3 m4 : 21|9@1+ (0.01,0) [0|5.12] "V" Vector__XXX
 SG_ BMS_ThermistorVoltages_Seg4_tm4 m4 : 30|9@1+ (0.01,0) [0|5.12] "V" Vector__XXX
 SG_ BMS_ThermistorVoltages_Seg4_tm5 m4 : 39|9@1+ (0.01,0) [0|5.12] "V" Vector__XXX
 SG_ BMS_ThermistorVoltages_Seg4_tm6 m4 : 48|9@1+ (0.01,0) [0|5.12] "V" Vector__XXX
 SG_ BMS_ThermistorVoltages_Seg4_tm7 m5 : 3|9@1+ (0.01,0) [0|5.12] "V" Vector__XXX
 SG_ BMS_ThermistorVoltages_Seg4_tm8 m5 : 12|9@1+ (0.01,0) [0|5.12] "V" Vector__XXX

BO_ 704 BMS_Temperatures: 8 BMS
 SG_ BMS_Temperatures_mux M : 0|3@1+ (1,0) [0|4] "" Vector__XXX
 SG_ BMS_Temperatures_Seg1_1 m0 : 3|8@1- (1,0) [-128|127] "C" Vector__XXX
 SG_ BMS_Temperatures_Seg1_2 m0 : 11|8@1- (1,0) [-128|127] "C" Vector__XXX
 SG_ BMS_Temperatures_Seg1_3 m0 : 19|8@1- (1,0) [-128|127] "C" Vector__XXX
 SG_ BMS_Temperatures_Seg1_4 m0 : 27|8@1- (1,0) [-128|127] "C" Vector__XXX
 SG_ BMS_Temperatures_Seg1_5 m0 : 35|8@1- (1,0) [-128|127] "C" Vector__XXX
 SG_ BMS_Temperatures_Seg1_6 m0 : 43|8@1- (1,0) [-128|127] "C" Vector__XXX
 SG_ BMS_Temperatures_Seg1_7 m0 : 51|8@1- (1,0) [-128|127] "C" Vector__XXX
 SG_ BMS_Temperatures_Seg1_8 m1 : 3|8@1- (1,0) [-128|127] "C" Vector__XXX
 SG_ BMS_Temperatures_Seg2_1 m1 : 11|8@1- (1,0) [-128|127] "C" Vector__XXX
 SG_ BMS_Temperatures_Seg2_2 m1 : 19|8@1- (1,0) [-128|127] "C" Vector__XXX
 SG_ BMS_Temperatures_Seg2_3 m1 : 27|8@1- (1,0) [-128|127] "C" Vector__XXX
 SG_ BMS_Temperatures_Seg2_4 m1 : 35|8@1- (1,0) [-128|127] "C" Vector__XXX
 SG_ BMS_Temperatures_Seg2_5 m1 : 43|8@1- (1,0) [-128|127] "C" Vector__XXX
 SG_ BMS_Temperatures_Seg2_6 m1 : 51|8@1- (1,0) [-128|127] "C" Vector__XXX
 SG_ BMS_Temperatures_Seg2_7 m2 : 3|8@1- (1,0) [-128|127] "C" Vector__XXX
 SG_ BMS_Temperatures_Seg2_8 m2 : 11|8@1- (1,0) [-128|127] "C" Vector__XXX
 SG_ BMS_Temperatures_Seg3_1 m2 : 19|8@1- (1,0) [-128|127] "C" Vector__XXX
 SG_ BMS_Temperatures_Seg3_2 m2 : 27|8@1- (1,0) [-128|127] "C" Vector__XXX
 SG_ BMS_Temperatures_Seg3_3 m2 : 35|8@1- (1,0) [-128|127] "C" Vector__XXX
 SG_ BMS_Temperatures_Seg3_4 m2 : 43|8@1- (1,0) [-128|127] "C" Vector__XXX
 SG_ BMS_Temperatures_Seg3_5 m2 : 51|8@1- (1,0) [-128|127] "C" Vector__XXX
 SG_ BMS_Temperatures_Seg3_6 m3 : 3|8@1- (1,0) [-128|127] "C" Vector__XXX
 SG_ BMS_Temperatures_Seg3_7 m3 : 11|8@1- (1,0) [-128|127] "C" Vector__XXX
 SG_ BMS_Temperatures_Seg3_8 m3 : 19|8@1- (1,0) [-128|127] "C" Vector__XXX
 SG_ BMS_Temperatures_Seg4_1 m3 : 27|8@1- (1,0) [-128|127] "C" Vector__XXX
 SG_ BMS_Temperatures_Seg4_2 m3 : 35|8@1- (1,0) [-128|127] "C" Vector__XXX
 SG_ BMS_Temperatures_Seg4_3 m3 : 43|8@1- (1,0) [-128|127] "C" Vector__XXX
 SG_ BMS_Temperatures_Seg4_4 m3 : 51|8@1- (1,0) [-128|127] "C" Vector__XXX
 SG_ BMS_Temperatures_Seg4_5 m4 : 3|8@1- (1,0) [-128|127] "C" Vector__XXX
 SG_ BMS_Temperatures_Seg4_6 m4 : 11|8@1- (1,0) [-128|127] "C" Vector__XXX
 SG_ BMS_Temperatures_Seg4_7 m4 : 19|8@1- (1,0) [-128|127] "C" Vector__XXX
 SG_ BMS_Temperatures_Seg4_8 m4 : 27|8@1- (1,0) [-128|127] "C" Vector__XXX

BO_ 800 BMS_DrainStatus: 8 BMS
 SG_ BMS_DrainStatus_mux M : 0|1@1+ (1,0) [0|1] "" Vector__XXX
 SG_ BMS_DrainStatus_Seg1_Cell1 m0 : 1|1@1+ (1,0) [0|1] "" Vector__XXX
 SG_ BMS_DrainStatus_Seg1_Cell2 m0 : 2|1@1+ (1,0) [0|1] "" Vector__XXX
 SG_ BMS_DrainStatus_Seg1_Cell3 m0 : 3|1@1+ (1,0) [0|1] "" Vector__XXX
 SG_ BMS_DrainStatus_Seg1_Cell4 m0 : 4|1@1+ (1,0) [0|1] "" Vector__XXX
 SG_ BMS_DrainStatus_Seg1_Cell5 m0 : 5|1@1+ (1,0) [0|1] "" Vector__XXX
 SG_ BMS_DrainStatus_Seg1_Cell6 m0 : 6|1@1+ (1,0) [0|1] "" Vector__XXX
 SG_ BMS_DrainStatus_Seg1_Cell7 m0 : 7|1@1+ (1,0) [0|1] "" Vector__XXX
 SG_ BMS_DrainStatus_Seg1_Cell8 m0 : 8|1@1+ (1,0) [0|1] "" Vector__XXX
 SG_ BMS_DrainStatus_Seg1_Cell9 m0 : 9|1@1+ (1,0) [0|1] "" Vector__XXX
 SG_ BMS_DrainStatus_Seg1_Cell10 m0 : 10|1@1+ (1,0) [0|1] "" Vector__XXX
 SG_ BMS_DrainStatus_Seg1_Cell11 m0 : 11|1@1+ (1,0) [0|1] "" Vector__XXX
 SG_ BMS_DrainStatus_Seg1_Cell12 m0 : 12|1@1+ (1,0) [0|1] "" Vector__XXX
 SG_ BMS_DrainStatus_Seg1_Cell13 m0 : 13|1@1+ (1,0) [0|1] "" Vector__XXX
 SG_ BMS_DrainStatus_Seg1_Cell14 m0 : 14|1@1+ (1,0) [0|1] "" Vector__XXX
 SG_ BMS_DrainStatus_Seg1_Cell15 m0 : 15|1@1+ (1,0) [0|1] "" Vector__XXX
 SG_ BMS_DrainStatus_Seg1_Cell16 m0 : 16|1@1+ (1,0) [0|1] "" Vector__XXX
 SG_ BMS_DrainStatus_Seg1_Cell17 m0 : 17|1@1+ (1,0) [0|1] "" Vector__XXX
 SG_ BMS_DrainStatus_Seg1_Cell18 m0 : 18|1@1+ (1,0) [0|1] "" Vector__XXX
 SG_ BMS_DrainStatus_Seg1_Cell19 m0 : 19|1@1+ (1,0) [0|1] "" Vector__XXX
 SG_ BMS_DrainStatus_Seg2_Cell1 m0 : 20|1@1+ (1,0) [0|1] "" Vector__XXX
 SG_ BMS_DrainStatus_Seg2_Cell2 m0 : 21|1@1+ (1,0) [0|1] "" Vector__XXX
 SG_ BMS_DrainStatus_Seg2_Cell3 m0 : 22|1@1+ (1,0) [0|1] "" Vector__XXX
 SG_ BMS_DrainStatus_Seg2_Cell4 m0 : 23|1@1+ (1,0) [0|1] "" Vector__XXX
 SG_ BMS_DrainStatus_Seg2_Cell5 m0 : 24|1@1+ (1,0) [0|1] "" Vector__XXX
 SG_ BMS_DrainStatus_Seg2_Cell6 m0 : 25|1@1+ (1,0) [0|1] "" Vector__XXX
 SG_ BMS_DrainStatus_Seg2_Cell7 m0 : 26|1@1+ (1,0) [0|1] "" Vector__XXX
 SG_ BMS_DrainStatus_Seg2_Cell8 m0 : 27|1@1+ (1,0) [0|1] "" Vector__XXX
 SG_ BMS_DrainStatus_Seg2_Cell9 m0 : 28|1@1+ (1,0) [0|1] "" Vector__XXX
 SG_ BMS_DrainStatus_Seg2_Cell10 m0 : 29|1@1+ (1,0) [0|1] "" Vector__XXX
 SG_ BMS_DrainStatus_Seg2_Cell11 m0 : 30|1@1+ (1,0) [0|1] "" Vector__XXX
 SG_ BMS_DrainStatus_Seg2_Cell12 m0 : 31|1@1+ (1,0) [0|1] "" Vector__XXX
 SG_ BMS_DrainStatus_Seg2_Cell13 m0 : 32|1@1+ (1,0) [0|1] "" Vector__XXX
 SG_ BMS_DrainStatus_Seg2_Cell14 m0 : 33|1@1+ (1,0) [0|1] "" Vector__XXX
 SG_ BMS_DrainStatus_Seg2_Cell15 m0 : 34|1@1+ (1,0) [0|1] "" Vector__XXX
 SG_ BMS_DrainStatus_Seg2_Cell16 m0 : 35|1@1+ (1,0) [0|1] "" Vector__XXX
 SG_ BMS_DrainStatus_Seg2_Cell17 m0 : 36|1@1+ (1,0) [0|1] "" Vector__XXX
 SG_ BMS_DrainStatus_Seg2_Cell18 m0 : 37|1@1+ (1,0) [0|1] "" Vector__XXX
 SG_ BMS_DrainStatus_Seg2_Cell19 m0 : 38|1@1+ (1,0) [0|1] "" Vector__XXX
 SG_ BMS_DrainStatus_Seg3_Cell1 m0 : 39|1@1+ (1,0) [0|1] "" Vector__XXX
 SG_ BMS_DrainStatus_Seg3_Cell2 m0 : 40|1@1+ (1,0) [0|1] "" Vector__XXX
 SG_ BMS_DrainStatus_Seg3_Cell3 m0 : 41|1@1+ (1,0) [0|1] "" Vector__XXX
 SG_ BMS_DrainStatus_Seg3_Cell4 m0 : 42|1@1+ (1,0) [0|1] "" Vector__XXX
 SG_ BMS_DrainStatus_Seg3_Cell5 m0 : 43|1@1+ (1,0) [0|1] "" Vector__XXX
 SG_ BMS_DrainStatus_Seg3_Cell6 m0 : 44|1@1+ (1,0) [0|1] "" Vector__XXX
 SG_ BMS_DrainStatus_Seg3_Cell7 m0 : 45|1@1+ (1,0) [0|1] "" Vector__XXX
 SG_ BMS_DrainStatus_Seg3_Cell8 m0 : 46|1@1+ (1,0) [0|1] "" Vector__XXX
 SG_ BMS_DrainStatus_Seg3_Cell9 m0 : 47|1@1+ (1,0) [0|1] "" Vector__XXX
 SG_ BMS_DrainStatus_Seg3_Cell10 m0 : 48|1@1+ (1,0) [0|1] "" Vector__XXX
 SG_ BMS_DrainStatus_Seg3_Cell11 m0 : 49|1@1+ (1,0) [0|1] "" Vector__XXX
 SG_ BMS_DrainStatus_Seg3_Cell12 m0 : 50|1@1+ (1,0) [0|1] "" Vector__XXX
 SG_ BMS_DrainStatus_Seg3_Cell13 m0 : 51|1@1+ (1,0) [0|1] "" Vector__XXX
 SG_ BMS_DrainStatus_Seg3_Cell14 m0 : 52|1@1+ (1,0) [0|1] "" Vector__XXX
 SG_ BMS_DrainStatus_Seg3_Cell15 m0 : 53|1@1+ (1,0) [0|1] "" Vector__XXX
 SG_ BMS_DrainStatus_Seg3_Cell16 m0 : 54|1@1+ (1,0) [0|1] "" Vector__XXX
 SG_ BMS_DrainStatus_Seg3_Cell17 m0 : 55|1@1+ (1,0) [0|1] "" Vector__XXX
 SG_ BMS_DrainStatus_Seg3_Cell18 m0 : 56|1@1+ (1,0) [0|1] "" Vector__XXX
 SG_ BMS_DrainStatus_Seg3_Cell19 m0 : 57|1@1+ (1,0) [0|1] "" Vector__XXX
 SG_ BMS_DrainStatus_Seg4_Cell1 m0 : 58|1@1+ (1,0) [0|1] "" Vector__XXX
 SG_ BMS_DrainStatus_Seg4_Cell2 m0 : 59|1@1+ (1,0) [0|1] "" Vector__XXX
 SG_ BMS_DrainStatus_Seg4_Cell3 m0 : 60|1@1+ (1,0) [0|1] "" Vector__XXX
 SG_ BMS_DrainStatus_Seg4_Cell4 m0 : 61|1@1+ (1,0) [0|1] "" Vector__XXX
 SG_ BMS_DrainStatus_Seg4_Cell5 m0 : 62|1@1+ (1,0) [0|1] "" Vector__XXX
 SG_ BMS_DrainStatus_Seg4_Cell6 m0 : 63|1@1+ (1,0) [0|1] "" Vector__XXX
 SG_ BMS_DrainStatus_Seg4_Cell7 m1 : 1|1@1+ (1,0) [0|1] "" Vector__XXX
 SG_ BMS_DrainStatus_Seg4_Cell8 m1 : 2|1@1+ (1,0) [0|1] "" Vector__XXX
 SG_ BMS_DrainStatus_Seg4_Cell9 m1 : 3|1@1+ (1,0) [0|1] "" Vector__XXX
 SG_ BMS_DrainStatus_Seg4_Cell10 m1 : 4|1@1+ (1,0) [0|1] "" Vector__XXX
 SG_ BMS_DrainStatus_Seg4_Cell11 m1 : 5|1@1+ (1,0) [0|1] "" Vector__XXX
 SG_ BMS_DrainStatus_Seg4_Cell12 m1 : 6|1@1+ (1,0) [0|1] "" Vector__XXX
 SG_ BMS_DrainStatus_Seg4_Cell13 m1 : 7|1@1+ (1,0) [0|1] "" Vector__XXX
 SG_ BMS_DrainStatus_Seg4_Cell14 m1 : 8|1@1+ (1,0) [0|1] "" Vector__XXX
 SG_ BMS_DrainStatus_Seg4_Cell15 m1 : 9|1@1+ (1,0) [0|1] "" Vector__XXX
 SG_ BMS_DrainStatus_Seg4_Cell16 m1 : 10|1@1+ (1,0) [0|1] "" Vector__XXX
 SG_ BMS_DrainStatus_Seg4_Cell17 m1 : 11|1@1+ (1,0) [0|1] "" Vector__XXX
 SG_ BMS_DrainStatus_Seg4_Cell18 m1 : 12|1@1+ (1,0) [0|1] "" Vector__XXX
 SG_ BMS_DrainStatus_Seg4_Cell19 m1 : 13|1@1+ (1,0) [0|1] "" Vector__XXX

BO_ 900 BMS_Current: 8 BMS
 SG_ BMS_InstCurrentFilt : 0|32@1- (0.001,0) [-100|250] "A"  DASH

BO_ 950 BMS_HardFaultIndicator: 8 BMS
 SG_ BMS_HardFaultIndicator_task : 0|4@1+ (1,0) [0|15] "" Vector__XXX

BO_ 951 BMS_Ref: 8 BMS
 SG_ BMS_Ref_mux M : 0|1@1+ (1,0) [0|1] "" Vector__XXX
 SG_ BMS_Ref_ref0 m0 : 1|9@1+ (0.01,0) [0|5.12] "V" Vector__XXX
 SG_ BMS_Ref_ref1 m0 : 10|9@1+ (0.01,0) [0|5.12] "V" Vector__XXX
 SG_ BMS_Ref_ref2 m0 : 19|9@1+ (0.01,0) [0|5.12] "V" Vector__XXX
 SG_ BMS_Ref_ref3 m0 : 28|9@1+ (0.01,0) [0|5.12] "V" Vector__XXX
 SG_ BMS_Ref_ref4 m0 : 37|9@1+ (0.01,0) [0|5.12] "V" Vector__XXX
 SG_ BMS_Ref_ref5 m0 : 46|9@1+ (0.01,0) [0|5.12] "V" Vector__XXX
 SG_ BMS_Ref_ref6 m1 : 1|9@1+ (0.01,0) [0|5.12] "V" Vector__XXX
 SG_ BMS_Ref_ref7 m1 : 10|9@1+ (0.01,0) [0|5.12] "V" Vector__XXX
 SG_ BMS_Ref_ref8 m1 : 19|9@1+ (0.01,0) [0|5.12] "V" Vector__XXX
 SG_ BMS_Ref_ref9 m1 : 28|9@1+ (0.01,0) [0|5.12] "V" Vector__XXX
 SG_ BMS_Ref_ref10 m1 : 37|9@1+ (0.01,0) [0|5.12] "V" Vector__XXX
 SG_ BMS_Ref_ref11 m1 : 46|9@1+ (0.01,0) [0|5.12] "V" Vector__XXX

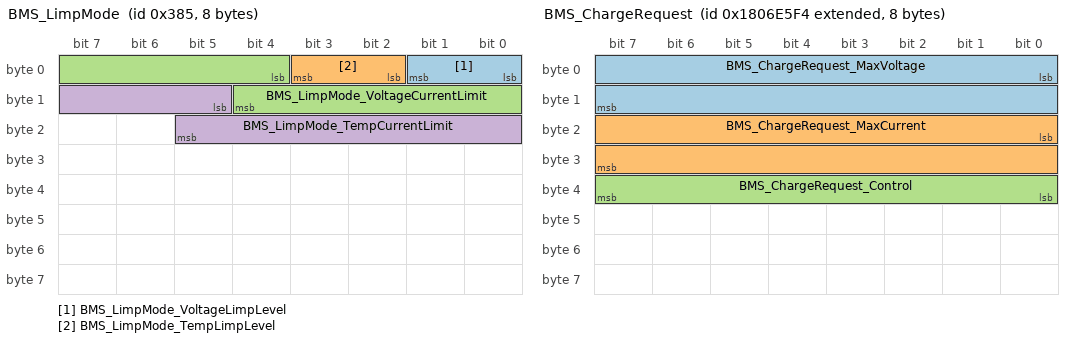
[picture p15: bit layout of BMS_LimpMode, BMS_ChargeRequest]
BO_ 901 BMS_LimpMode: 8 BMS
 SG_ BMS_LimpMode_VoltageLimpLevel : 0|2@1+ (1,0) [0|4] "" Vector__XXX
 SG_ BMS_LimpMode_TempLimpLevel : 2|2@1+ (1,0) [0|4] "" Vector__XXX
 SG_ BMS_LimpMode_VoltageCurrentLimit : 4|9@1- (1,0) [-100|500] "A" Vector__XXX
 SG_ BMS_LimpMode_TempCurrentLimit : 13|9@1- (1,0) [-100|500] "A" Vector__XXX

BO_ 2550588916 BMS_ChargeRequest: 8 BMS
 SG_ BMS_ChargeRequest_MaxVoltage : 0|16@1+ (0.1,0) [0|6553.5] "V"  CHG
 SG_ BMS_ChargeRequest_MaxCurrent : 16|16@1+ (0.1,0) [0|6553.5] "A"  CHG
 SG_ BMS_ChargeRequest_Control : 32|8@1+ (1,0) [0|1] ""  CHG

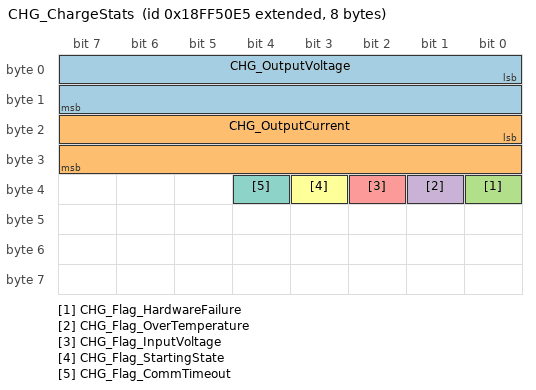
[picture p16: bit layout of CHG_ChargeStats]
BO_ 2566869221 CHG_ChargeStats: 8 CHG
 SG_ CHG_OutputVoltage : 0|16@1+ (0.1,0) [0|6553.5] "V" Vector__XXX
 SG_ CHG_OutputCurrent : 16|16@1+ (0.1,0) [0|6553.5] "A" Vector__XXX
 SG_ CHG_Flag_HardwareFailure : 32|1@1+ (1,0) [0|1] "" Vector__XXX
 SG_ CHG_Flag_OverTemperature : 33|1@1+ (1,0) [0|1] "" Vector__XXX
 SG_ CHG_Flag_InputVoltage : 34|1@1+ (1,0) [0|1] "" Vector__XXX
 SG_ CHG_Flag_StartingState : 35|1@1+ (1,0) [0|1] "" Vector__XXX
 SG_ CHG_Flag_CommTimeout : 36|1@1+ (1,0) [0|1] "" Vector__XXX

CM_ BU_ C70 "Bosch C70 Data Logger";
CM_ BU_ VC "Vehicle Controller";
CM_ BU_ MCU "Motor Control Unit";
CM_ BU_ BMS "Battery Management System";
CM_ BU_ CHG "Charge Cart";
CM_ BU_ DASH "Dashboard Display";
CM_ SG_ 601 BMS_Overview_Drains "Number of cells currently draining";
CM_ BO_ 1790 "Wheel speeds, relayed by C70";
CM_ BO_ 1791 "Brake Pressures, relayed by C70";
BA_DEF_ SG_  "SystemSignalLongSymbol" STRING ;
BA_DEF_DEF_  "SystemSignalLongSymbol" "";
BA_ "SystemSignalLongSymbol" SG_ 305 VC_ShutdownStatus_BSPD_signal_lo "VC_ShutdownStatus_BSPD_signal_lost";
BA_ "SystemSignalLongSymbol" SG_ 311 VC_FaultVector_BRAKE_SENSOR_IRRA "VC_FaultVector_BRAKE_SENSOR_IRRATIONAL";
BA_ "SystemSignalLongSymbol" SG_ 311 VC_FaultVector_ACCELERATOR_SENSO "VC_FaultVector_ACCELERATOR_SENSOR_IRRATIONAL";
BA_ "SystemSignalLongSymbol" SG_ 311 VC_FaultVector_APPS_SENSOR_DISAG "VC_FaultVector_APPS_SENSOR_DISAGREEMENT";
BA_ "SystemSignalLongSymbol" SG_ 469 D1_HV_Input_Current_Sensor_Valid "D1_HV_Input_Current_Sensor_Validity";
BA_ "SystemSignalLongSymbol" SG_ 700 BMS_FaultVector_SLAVE_COMM_DRAIN "BMS_FaultVector_SLAVE_COMM_DRAIN_REQUEST";
BA_ "SystemSignalLongSymbol" SG_ 700 BMS_FaultVector_CURRENT_SENSOR_C "BMS_FaultVector_CURRENT_SENSOR_COMM";
BA_ "SystemSignalLongSymbol" SG_ 700 BMS_FaultVector_CELL_VOLTAGE_IRR "BMS_FaultVector_CELL_VOLTAGE_IRRATIONAL";
BA_ "SystemSignalLongSymbol" SG_ 700 BMS_FaultVector_CELL_VOLTAGE_DIF "BMS_FaultVector_CELL_VOLTAGE_DIFF";
BA_ "SystemSignalLongSymbol" SG_ 700 BMS_FaultVector_TEMPERATURE_IRRA "BMS_FaultVector_TEMPERATURE_IRRATIONAL";
BA_ "SystemSignalLongSymbol" SG_ 701 BMS_FaultAlert_cell_comm_slave_b "BMS_FaultAlert_cell_comm_slave_board_num";
BA_ "SystemSignalLongSymbol" SG_ 701 BMS_FaultAlert_temp_comm_slave_b "BMS_FaultAlert_temp_comm_slave_board_num";
BA_ "SystemSignalLongSymbol" SG_ 701 BMS_FaultAlert_drain_comm_slave_ "BMS_FaultAlert_drain_comm_slave_board_num";
BA_ "SystemSignalLongSymbol" SG_ 701 BMS_FaultAlert_irrational_voltag "BMS_FaultAlert_irrational_voltage";
BA_ "SystemSignalLongSymbol" SG_ 701 BMS_FaultAlert_lowest_cell_volta "BMS_FaultAlert_lowest_cell_voltage";
BA_ "SystemSignalLongSymbol" SG_ 701 BMS_FaultAlert_irrational_temper "BMS_FaultAlert_irrational_temperature";
VAL_ 301 VC_Status_VehicleState 0 "VehicleState_NOT_READY" 1 "VehicleState_STARTUP" 2 "VehicleState_READY_TO_DRIVE" 3 "VehicleState_FAULTED" ;
VAL_ 315 VC_HardFaultIndicator_task 0 "unknown" 1 "task_100Hz" ;
VAL_ 192 Direction_Command 0 "CW" 1 "CCW" ;
VAL_ 192 Inverter_Discharge 0 "Discharge Disable" 1 "Discharge Enable (if EEPROM parameter is set)" ;
VAL_ 170 D2_Inverter_State 0 "Power up" 1 "Stop" 2 "Open Loop" 3 "Closed Loop" 4 "Internal State" 5 "Internal State" 6 "Internal State" 7 "Internal State" 8 "Idle Run" 9 "Idle Stop" 10 "Internal State" 11 "Intern State" 12 "Internal State" ;
VAL_ 170 D1_VSM_State 0 "VSM Start State" 1 "Pre-Charge Init state" 2 "pre-charge active state" 3 "pre-charge complete state" 4 "VSM wait state" 5 "VSM ready state" 6 "Motor Running State" 7 "blink fault code state" 14 "Shutdown state for Key Switch Mode 1" 15 "Reset the inverter" ;
VAL_ 600 BMS_Status_ChargeState 0 "ChargeState_DISCONNECTED" 1 "ChargeState_CONNECTED_COMPLETE" 2 "ChargeState_CONNECTED_BALANCING" 3 "ChargeState_CONNECTED_CHARGING" 4 "ChargeState_CONNECTED_BALANCE_SENSING" ;
VAL_ 701 BMS_FaultAlert_code 0 "FaultCode_SLAVE_COMM_CELLS" 1 "FaultCode_SLAVE_COMM_TEMPS" 2 "FaultCode_SLAVE_COMM_DRAIN_REQUEST" 3 "FaultCode_CURRENT_SENSOR_COMM" 4 "FaultCode_OVER_CURRENT" 5 "FaultCode_CELL_VOLTAGE_IRRATIONAL" 6 "FaultCode_CELL_VOLTAGE_DIFF" 7 "Faultcode_OUT_OF_JUICE" 8 "FaultCode_TEMPERATURE_IRRATIONAL" 9 "FaultCode_OVER_TEMP" 10 "FaultCode_DRAIN_FAILURE" ;
VAL_ 950 BMS_HardFaultIndicator_task 0 "unknown" 1 "task_1Hz" 2 "task_10Hz" 3 "task_1kHz" 4 "can_rx_task" ;
VAL_ 901 BMS_LimpMode_VoltageLimpLevel 0 "LimpModeLevel_NO_LIMP" 1 "LimpModeLevel_LEVEL_1" 2 "LimpModeLevel_LEVEL_2" 3 "LimpModeLevel_LEVEL_3" ;
VAL_ 901 BMS_LimpMode_TempLimpLevel 0 "LimpModeLevel_NO_LIMP" 1 "LimpModeLevel_LEVEL_1" 2 "LimpModeLevel_LEVEL_2" 3 "LimpModeLevel_LEVEL_3" ;
